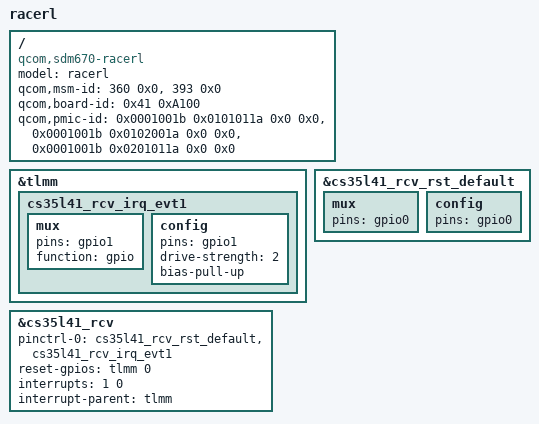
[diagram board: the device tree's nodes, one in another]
/* Copyright (c) 2018, The Linux Foundation. All rights reserved.
 *
 * This program is free software; you can redistribute it and/or modify
 * it under the terms of the GNU General Public License version 2 and
 * only version 2 as published by the Free Software Foundation.
 *
 * This program is distributed in the hope that it will be useful,
 * but WITHOUT ANY WARRANTY; without even the implied warranty of
 * MERCHANTABILITY or FITNESS FOR A PARTICULAR PURPOSE.  See the
 * GNU General Public License for more details.
 */

/dts-v1/;
/plugin/;

#include "sdm710-racerl-common-overlay.dtsi"

/ {
	model = "racerl";
	compatible = "qcom,sdm670-racerl", "qcom,sdm670-moto", "qcom,racerl";
	qcom,msm-id =	<360 0x0>,
			<393 0x0>;
	qcom,board-id = <0x41 0xA100>;
	qcom,pmic-id = <0x0001001b 0x0101011a 0x0 0x0>,
		       <0x0001001b 0x0102001a 0x0 0x0>,
		       <0x0001001b 0x0201011a 0x0 0x0>;
};

&tlmm {
	cs35l41_rcv_irq_evt1: cs35l41_rcv_irq_evt1 {
		mux {
			pins = "gpio1";
			function = "gpio";
		};
		config {
			pins = "gpio1";
			drive-strength = <2>;
			bias-pull-up;
		};
	};
};

&cs35l41_rcv_rst_default {
	mux {
		pins = "gpio0";
	};
	config {
		pins = "gpio0";
	};
};

&cs35l41_rcv {
	pinctrl-0 = <&cs35l41_rcv_rst_default &cs35l41_rcv_irq_evt1>;
	reset-gpios = <&tlmm 0 0>;

	interrupts = <1 0>;
	interrupt-parent = <&tlmm>;
	interrupt-names = "prince_rcv_irq";
};
